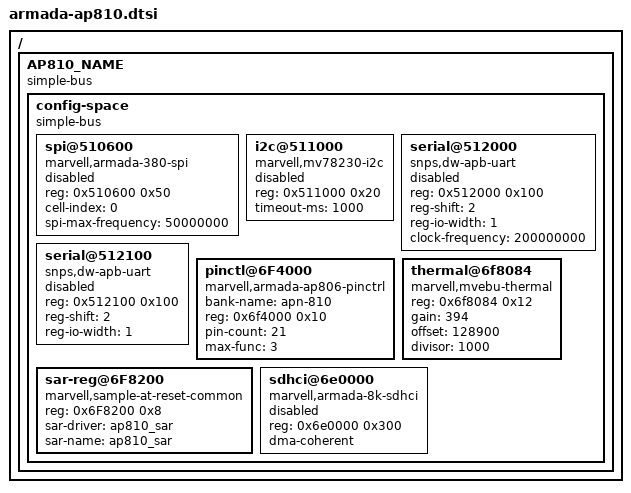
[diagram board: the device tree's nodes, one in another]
/*
 * Copyright (C) 2017 Marvell International Ltd.
 *
 * SPDX-License-Identifier:    GPL-2.0
 * https://spdx.org/licenses
 */

/*
 * Device Tree file for Marvell Common Armada AP810.
 */

/{
	AP810_NAME {
		#address-cells = <2>;
		#size-cells = <2>;
		compatible = "simple-bus";
		ranges;

		config-space {
			#address-cells = <1>;
			#size-cells = <1>;
			compatible = "simple-bus";
			ranges = <0x0 0x0 AP810_BASE 0x4000000>;

			AP810_LABEL(spi): spi@510600 {
				compatible = "marvell,armada-380-spi";
				reg = <0x510600 0x50>;
				#address-cells = <1>;
				#size-cells = <0>;
				cell-index = <0>;
				spi-max-frequency = <50000000>;
				status = "disabled";
			};

			AP810_LABEL(i2c0): i2c@511000 {
				compatible = "marvell,mv78230-i2c";
				reg = <0x511000 0x20>;
				#address-cells = <1>;
				#size-cells = <0>;
				timeout-ms = <1000>;
				status = "disabled";
			};

			AP810_LABEL(uart0): serial@512000 {
				compatible = "snps,dw-apb-uart";
				reg = <0x512000 0x100>;
				reg-shift = <2>;
				reg-io-width = <1>;
				status = "disabled";
				clock-frequency = <200000000>;
			};

			AP810_LABEL(uart1): serial@512100 {
				compatible = "snps,dw-apb-uart";
				reg = <0x512100 0x100>;
				reg-shift = <2>;
				reg-io-width = <1>;
				status = "disabled";
			};

			AP810_LABEL(pinctl): pinctl@6F4000 {
				compatible = "marvell,armada-ap806-pinctrl";
				bank-name ="apn-810";
				reg = <0x6f4000 0x10>;
				pin-count = <21>;
				max-func = <3>;
			};

			AP810_LABEL(thermal): thermal@6f8084 {
				compatible = "marvell,mvebu-thermal", "marvell,thermal-ext-sensor";
				reg = <0x6f8084 0x12>;
				gain = <394>;
				offset = <128900>;
				divisor = <1000>;
				status = "okay";
			};

			AP810_LABEL(sar_reg): sar-reg@6F8200 {
				compatible = "marvell,sample-at-reset-common", "marvell,sample-at-reset-ap810";
				reg = <0x6F8200 0x8>;
				sar-driver = "ap810_sar";
				sar-name = "ap810_sar";
				status = "okay";
			};

			AP810_LABEL(sdhci0): sdhci@6e0000 {
				compatible = "marvell,armada-8k-sdhci";
				reg = <0x6e0000 0x300>;
				dma-coherent;
				status = "disabled";
			};
		};
	};
};
